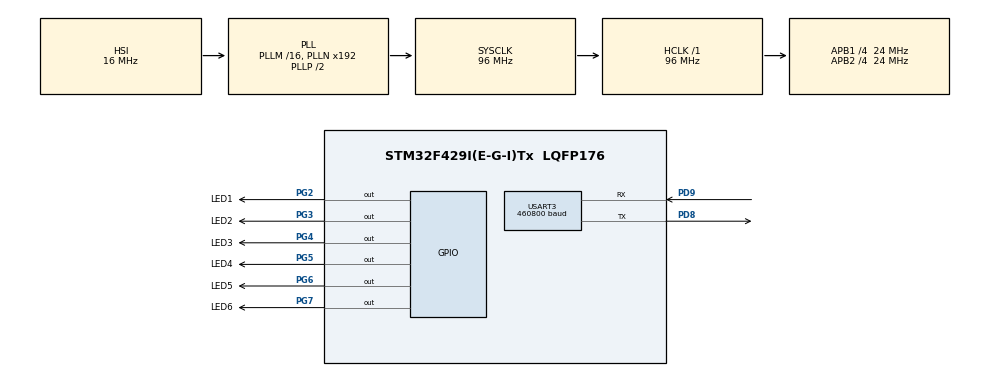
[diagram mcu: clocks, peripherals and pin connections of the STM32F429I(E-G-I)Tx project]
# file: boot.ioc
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Dma.Request0=USART3_RX
Dma.USART3_RX.0.Direction=DMA_PERIPH_TO_MEMORY
Dma.USART3_RX.0.FIFOMode=DMA_FIFOMODE_DISABLE
Dma.USART3_RX.0.Instance=DMA1_Stream1
Dma.USART3_RX.0.MemDataAlignment=DMA_MDATAALIGN_BYTE
Dma.USART3_RX.0.MemInc=DMA_MINC_ENABLE
Dma.USART3_RX.0.Mode=DMA_NORMAL
Dma.USART3_RX.0.PeriphDataAlignment=DMA_PDATAALIGN_BYTE
Dma.USART3_RX.0.PeriphInc=DMA_PINC_DISABLE
Dma.USART3_RX.0.Priority=DMA_PRIORITY_HIGH
Mcu.Family=STM32F4
Mcu.Name=STM32F429I(E-G-I)Tx
Mcu.Package=LQFP176
NVIC.DMA1_Stream1_IRQn=true\:0\:0\:false\:false\:true
NVIC.PriorityGroup=NVIC_PRIORITYGROUP_4
NVIC.TIM1_UP_TIM10_IRQn=true\:0\:0\:false\:false\:true
NVIC.USART3_IRQn=true\:0\:0\:false\:false\:true
PD8.Mode=Asynchronous
PD8.Signal=USART3_TX
PD9.Mode=Asynchronous
PD9.Signal=USART3_RX
PG2.GPIO_Label=LED1
PG2.GPIO_ModeDefaultOutputPP=GPIO_MODE_OUTPUT_OD
PG2.GPIO_PuPd=GPIO_NOPULL
PG2.PinState=GPIO_PIN_SET
PG2.Signal=GPIO_Output
PG3.GPIO_Label=LED2
PG3.GPIO_ModeDefaultOutputPP=GPIO_MODE_OUTPUT_OD
PG3.GPIO_Speed=GPIO_SPEED_FREQ_LOW
PG3.PinState=GPIO_PIN_SET
PG3.Signal=GPIO_Output
PG4.GPIO_Label=LED3
PG4.GPIO_ModeDefaultOutputPP=GPIO_MODE_OUTPUT_OD
PG4.PinState=GPIO_PIN_SET
PG4.Signal=GPIO_Output
PG5.GPIO_Label=LED4
PG5.GPIO_ModeDefaultOutputPP=GPIO_MODE_OUTPUT_OD
PG5.PinState=GPIO_PIN_SET
PG5.Signal=GPIO_Output
PG6.GPIO_Label=LED5
PG6.GPIO_ModeDefaultOutputPP=GPIO_MODE_OUTPUT_OD
PG6.PinState=GPIO_PIN_SET
PG6.Signal=GPIO_Output
PG7.GPIO_Label=LED6
PG7.GPIO_ModeDefaultOutputPP=GPIO_MODE_OUTPUT_OD
PG7.PinState=GPIO_PIN_SET
PG7.Signal=GPIO_Output
ProjectManager.HeapSize=0x200
ProjectManager.StackSize=0x400
ProjectManager.TargetToolchain=MDK-ARM V5
RCC.AHBFreq_Value=96000000
RCC.APB1CLKDivider=RCC_HCLK_DIV4
RCC.APB1Freq_Value=24000000
RCC.APB1TimFreq_Value=48000000
RCC.APB2CLKDivider=RCC_HCLK_DIV4
RCC.APB2Freq_Value=24000000
RCC.APB2TimFreq_Value=48000000
RCC.CortexFreq_Value=96000000
RCC.HCLKFreq_Value=96000000
RCC.HSE_VALUE=25000000
RCC.HSI_VALUE=16000000
RCC.LSE_VALUE=32768
RCC.SYSCLKFreq_VALUE=96000000
RCC.SYSCLKSource=RCC_SYSCLKSOURCE_PLLCLK
RCC.VCOOutputFreq_Value=192000000
TIM1.ClockDivision=TIM_CLOCKDIVISION_DIV2
TIM1.Period=30000
TIM1.Prescaler=48
USART3.BaudRate=460800
USART3.VirtualMode=VM_ASYNC
VP_TIM1_VS_ClockSourceINT.Mode=Internal
board=boot

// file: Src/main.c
/**
  ******************************************************************************
  * File Name          : main.c
  * Description        : Main program body
  ******************************************************************************
  ** This notice applies to any and all portions of this file
  * that are not between comment pairs USER CODE BEGIN and
  * USER CODE END. Other portions of this file, whether
  * inserted by the user or by software development tools
  * are owned by their respective copyright owners.
  *
  * COPYRIGHT(c) 2017 STMicroelectronics
  *
  * Redistribution and use in source and binary forms, with or without modification,
  * are permitted provided that the following conditions are met:
  *   1. Redistributions of source code must retain the above copyright notice,
  *      this list of conditions and the following disclaimer.
  *   2. Redistributions in binary form must reproduce the above copyright notice,
  *      this list of conditions and the following disclaimer in the documentation
  *      and/or other materials provided with the distribution.
  *   3. Neither the name of STMicroelectronics nor the names of its contributors
  *      may be used to endorse or promote products derived from this software
  *      without specific prior written permission.
  *
  * THIS SOFTWARE IS PROVIDED BY THE COPYRIGHT HOLDERS AND CONTRIBUTORS "AS IS"
  * AND ANY EXPRESS OR IMPLIED WARRANTIES, INCLUDING, BUT NOT LIMITED TO, THE
  * IMPLIED WARRANTIES OF MERCHANTABILITY AND FITNESS FOR A PARTICULAR PURPOSE ARE
  * DISCLAIMED. IN NO EVENT SHALL THE COPYRIGHT HOLDER OR CONTRIBUTORS BE LIABLE
  * FOR ANY DIRECT, INDIRECT, INCIDENTAL, SPECIAL, EXEMPLARY, OR CONSEQUENTIAL
  * DAMAGES (INCLUDING, BUT NOT LIMITED TO, PROCUREMENT OF SUBSTITUTE GOODS OR
  * SERVICES; LOSS OF USE, DATA, OR PROFITS; OR BUSINESS INTERRUPTION) HOWEVER
  * CAUSED AND ON ANY THEORY OF LIABILITY, WHETHER IN CONTRACT, STRICT LIABILITY,
  * OR TORT (INCLUDING NEGLIGENCE OR OTHERWISE) ARISING IN ANY WAY OUT OF THE USE
  * OF THIS SOFTWARE, EVEN IF ADVISED OF THE POSSIBILITY OF SUCH DAMAGE.
  *
  ******************************************************************************
  */
#include "main.h"
#include "stm32f4xx_hal.h"

#define Watch_dog_io_Pin GPIO_PIN_9
#define Watch_dog_io_GPIO_Port GPIOE

/* USER CODE BEGIN Includes */
extern void re_send_to_n1(void);
extern void send_to_n1(void);
extern void start_from_n1_dma_receive();
/* USER CODE END Includes */

TIM_HandleTypeDef htim1;

UART_HandleTypeDef huart3;
DMA_HandleTypeDef hdma_usart3_rx;

/* USER CODE BEGIN PV */
/* Private variables ---------------------------------------------------------*/

/* USER CODE END PV */

void SystemClock_Config(void);
static void MX_GPIO_Init(void);
static void MX_DMA_Init(void);
static void MX_USART3_UART_Init(void);
static void MX_TIM1_Init(void);

/* USER CODE BEGIN PFP */
/* Private function prototypes -----------------------------------------------*/

/* USER CODE END PFP */

/* USER CODE BEGIN 0 */
int start_app = 0;
extern int sec;
extern int ms_500;
/* USER CODE END 0 */

int main(void)
{

  /* USER CODE BEGIN 1 */
	int sec_v = 0;
	void( *pfunc)() = (void( *))(*((uint32_t *)0x08004004));
  /* USER CODE END 1 */

  /* MCU Configuration----------------------------------------------------------*/

  /* Reset of all peripherals, Initializes the Flash interface and the Systick. */
  HAL_Init();

  /* Configure the system clock */
  SystemClock_Config();

  /* Initialize all configured peripherals */
  MX_GPIO_Init();
  MX_DMA_Init();
  MX_USART3_UART_Init();
  MX_TIM1_Init();

  /* USER CODE BEGIN 2 */
	HAL_TIM_Base_Start_IT(&htim1);
	start_from_n1_dma_receive();
	//send_to_n1();
  /* USER CODE END 2 */

  /* Infinite loop */
  while (1)
  {

  /* USER CODE BEGIN 3 */
		re_send_to_n1();
		HAL_GPIO_TogglePin(Watch_dog_io_GPIO_Port,Watch_dog_io_Pin);

		if(start_app == 0 && sec>3)
		{

				HAL_TIM_Base_Stop(&htim1);
				HAL_DMA_Abort(&hdma_usart3_rx);
				HAL_UART_DeInit(&huart3);
				HAL_NVIC_DisableIRQ(DMA1_Stream1_IRQn);
				__set_MSP(*((uint32_t *)0x08004000));
				pfunc();
		}
		else if(start_app == 0 && ms_500<6 && sec_v!=ms_500)
		{
			sec_v = ms_500;
			HAL_GPIO_TogglePin(LED1_GPIO_Port,LED1_Pin);

		}
		else if(start_app == 1)
		{
			HAL_GPIO_TogglePin(LED5_GPIO_Port,LED5_Pin);
		}
  }
  /* USER CODE END 3 */

}

/** System Clock Configuration
*/
void SystemClock_Config(void)
{

  RCC_OscInitTypeDef RCC_OscInitStruct;
  RCC_ClkInitTypeDef RCC_ClkInitStruct;

    /**Configure the main internal regulator output voltage
    */
  __HAL_RCC_PWR_CLK_ENABLE();

  __HAL_PWR_VOLTAGESCALING_CONFIG(PWR_REGULATOR_VOLTAGE_SCALE3);

    /**Initializes the CPU, AHB and APB busses clocks
    */
  RCC_OscInitStruct.OscillatorType = RCC_OSCILLATORTYPE_HSI;
  RCC_OscInitStruct.HSIState = RCC_HSI_ON;
  RCC_OscInitStruct.HSICalibrationValue = 16;
  RCC_OscInitStruct.PLL.PLLState = RCC_PLL_ON;
  RCC_OscInitStruct.PLL.PLLSource = RCC_PLLSOURCE_HSI;
  RCC_OscInitStruct.PLL.PLLM = 16;
  RCC_OscInitStruct.PLL.PLLN = 192;
  RCC_OscInitStruct.PLL.PLLP = RCC_PLLP_DIV2;
  RCC_OscInitStruct.PLL.PLLQ = 4;
  if (HAL_RCC_OscConfig(&RCC_OscInitStruct) != HAL_OK)
  {
    _Error_Handler(__FILE__, __LINE__);
  }

    /**Initializes the CPU, AHB and APB busses clocks
    */
  RCC_ClkInitStruct.ClockType = RCC_CLOCKTYPE_HCLK|RCC_CLOCKTYPE_SYSCLK
                              |RCC_CLOCKTYPE_PCLK1|RCC_CLOCKTYPE_PCLK2;
  RCC_ClkInitStruct.SYSCLKSource = RCC_SYSCLKSOURCE_PLLCLK;
  RCC_ClkInitStruct.AHBCLKDivider = RCC_SYSCLK_DIV1;
  RCC_ClkInitStruct.APB1CLKDivider = RCC_HCLK_DIV4;
  RCC_ClkInitStruct.APB2CLKDivider = RCC_HCLK_DIV4;

  if (HAL_RCC_ClockConfig(&RCC_ClkInitStruct, FLASH_LATENCY_3) != HAL_OK)
  {
    _Error_Handler(__FILE__, __LINE__);
  }

    /**Configure the Systick interrupt time
    */
  HAL_SYSTICK_Config(HAL_RCC_GetHCLKFreq()/1000);

    /**Configure the Systick
    */
  HAL_SYSTICK_CLKSourceConfig(SYSTICK_CLKSOURCE_HCLK);

  /* SysTick_IRQn interrupt configuration */
  HAL_NVIC_SetPriority(SysTick_IRQn, 0, 0);
}

/* TIM1 init function */
static void MX_TIM1_Init(void)
{

  TIM_ClockConfigTypeDef sClockSourceConfig;
  TIM_MasterConfigTypeDef sMasterConfig;

  htim1.Instance = TIM1;
  htim1.Init.Prescaler = 96;
  htim1.Init.CounterMode = TIM_COUNTERMODE_UP;
  htim1.Init.Period = 30000;
  htim1.Init.ClockDivision = TIM_CLOCKDIVISION_DIV2;
  htim1.Init.RepetitionCounter = 0;
  if (HAL_TIM_Base_Init(&htim1) != HAL_OK)
  {
    _Error_Handler(__FILE__, __LINE__);
  }

  sClockSourceConfig.ClockSource = TIM_CLOCKSOURCE_INTERNAL;
  if (HAL_TIM_ConfigClockSource(&htim1, &sClockSourceConfig) != HAL_OK)
  {
    _Error_Handler(__FILE__, __LINE__);
  }

  sMasterConfig.MasterOutputTrigger = TIM_TRGO_RESET;
  sMasterConfig.MasterSlaveMode = TIM_MASTERSLAVEMODE_DISABLE;
  if (HAL_TIMEx_MasterConfigSynchronization(&htim1, &sMasterConfig) != HAL_OK)
  {
    _Error_Handler(__FILE__, __LINE__);
  }

}

/* USART3 init function */
static void MX_USART3_UART_Init(void)
{

  huart3.Instance = USART3;
  huart3.Init.BaudRate = 460800;
  huart3.Init.WordLength = UART_WORDLENGTH_8B;
  huart3.Init.StopBits = UART_STOPBITS_1;
  huart3.Init.Parity = UART_PARITY_NONE;
  huart3.Init.Mode = UART_MODE_TX_RX;
  huart3.Init.HwFlowCtl = UART_HWCONTROL_NONE;
  huart3.Init.OverSampling = UART_OVERSAMPLING_16;
  if (HAL_UART_Init(&huart3) != HAL_OK)
  {
    _Error_Handler(__FILE__, __LINE__);
  }

}

static void MX_DMA_Init(void)
{
  /* DMA controller clock enable */
  __HAL_RCC_DMA1_CLK_ENABLE();

  /* DMA interrupt init */
  /* DMA1_Stream1_IRQn interrupt configuration */
  HAL_NVIC_SetPriority(DMA1_Stream1_IRQn, 0, 0);
  HAL_NVIC_EnableIRQ(DMA1_Stream1_IRQn);

}
#define Watch_dog_io_Pin GPIO_PIN_9
/** Configure pins as
        * Analog
        * Input
        * Output
        * EVENT_OUT
        * EXTI
*/
static void MX_GPIO_Init(void)
{

  GPIO_InitTypeDef GPIO_InitStruct;

  /* GPIO Ports Clock Enable */
  __HAL_RCC_GPIOD_CLK_ENABLE();
  __HAL_RCC_GPIOG_CLK_ENABLE();
	__HAL_RCC_GPIOE_CLK_ENABLE();
  /*Configure GPIO pin Output Level */
  HAL_GPIO_WritePin(GPIOG, LED1_Pin|LED2_Pin|LED3_Pin|LED4_Pin
                          |LED5_Pin|LED6_Pin, GPIO_PIN_SET);

  /*Configure GPIO pins : LED1_Pin LED2_Pin LED3_Pin LED4_Pin
                           LED5_Pin LED6_Pin */
  GPIO_InitStruct.Pin = LED1_Pin|LED2_Pin|LED3_Pin|LED4_Pin
                          |LED5_Pin|LED6_Pin;
  GPIO_InitStruct.Mode = GPIO_MODE_OUTPUT_OD;
  GPIO_InitStruct.Pull = GPIO_NOPULL;
  GPIO_InitStruct.Speed = GPIO_SPEED_FREQ_LOW;
  HAL_GPIO_Init(GPIOG, &GPIO_InitStruct);

  /*Configure GPIO pins : Watch_dog_io_Pin SPI4_rf_cs_Pin */
  GPIO_InitStruct.Pin = Watch_dog_io_Pin;
  GPIO_InitStruct.Mode = GPIO_MODE_OUTPUT_PP;
  GPIO_InitStruct.Pull = GPIO_PULLUP;
  GPIO_InitStruct.Speed = GPIO_SPEED_FREQ_VERY_HIGH;
  HAL_GPIO_Init(GPIOE, &GPIO_InitStruct);

}

void _Error_Handler(char * file, int line)
{
  while(1)
  {
  }
}

/************************ (C) COPYRIGHT STMicroelectronics *****END OF FILE****/
